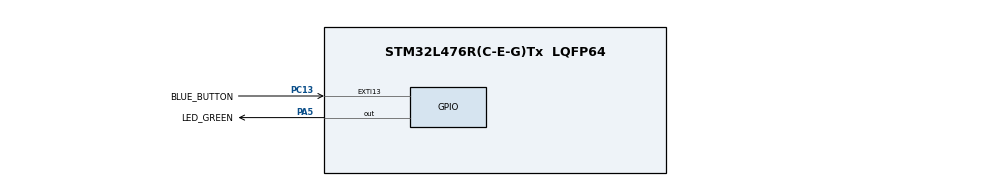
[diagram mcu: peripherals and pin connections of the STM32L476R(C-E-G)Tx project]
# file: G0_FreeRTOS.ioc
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FREERTOS.BinarySemaphores01=Binary_Sem,Dynamic,NULL
FREERTOS.Tasks01=Task1,0,128,Task1_App,Default,NULL,Dynamic,NULL,NULL;Task2,0,128,Task2_App,Default,NULL,Dynamic,NULL,NULL
FREERTOS.configUSE_NEWLIB_REENTRANT=1
Mcu.Family=STM32L4
Mcu.Name=STM32L476R(C-E-G)Tx
Mcu.Package=LQFP64
NVIC.EXTI15_10_IRQn=true\:5\:0\:false\:false\:true\:true\:true\:true\:true
NVIC.PriorityGroup=NVIC_PRIORITYGROUP_4
NVIC.TIM6_DAC_IRQn=true\:15\:0\:false\:false\:true\:false\:false\:true\:true
NVIC.TimeBase=TIM6_DAC_IRQn
NVIC.TimeBaseIP=TIM6
PA13\ (JTMS-SWDIO).Mode=Serial_Wire
PA13\ (JTMS-SWDIO).Signal=SYS_JTMS-SWDIO
PA14\ (JTCK-SWCLK).Mode=Serial_Wire
PA14\ (JTCK-SWCLK).Signal=SYS_JTCK-SWCLK
PA5.GPIO_Label=LED_GREEN
PA5.Signal=GPIO_Output
PC13.GPIO_Label=BLUE_BUTTON
PC13.GPIO_ModeDefaultEXTI=GPIO_MODE_IT_FALLING
PC13.Signal=GPXTI13
ProjectManager.HeapSize=0x200
ProjectManager.StackSize=0x400
ProjectManager.TargetToolchain=STM32CubeIDE
RCC.HSE_VALUE=8000000
RCC.HSI_VALUE=16000000
RCC.LSE_VALUE=32768
RCC.MSI_VALUE=4000000
RCC.VCOOutputFreq_Value=32000000
VP_FREERTOS_VS_CMSIS_V1.Mode=CMSIS_V1
VP_SYS_VS_tim6.Mode=TIM6
board=custom

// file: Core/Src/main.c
/* USER CODE BEGIN Header */
/**
  ******************************************************************************
  * @file           : main.c
  * @brief          : Main program body
  ******************************************************************************
  * @attention
  *
  * Copyright (c) 2023 STMicroelectronics.
  * All rights reserved.
  *
  * This software is licensed under terms that can be found in the LICENSE file
  * in the root directory of this software component.
  * If no LICENSE file comes with this software, it is provided AS-IS.
  *
  ******************************************************************************
  */
/* USER CODE END Header */
#include "main.h"
#include "cmsis_os.h"

osThreadId Task1Handle;
osThreadId Task2Handle;
osSemaphoreId Binary_SemHandle;

void SystemClock_Config(void);
static void MX_GPIO_Init(void);
void Task1_App(void const * argument);
void Task2_App(void const * argument);

int main(void)
{

  /* MCU Configuration--------------------------------------------------------*/

  /* Reset of all peripherals, Initializes the Flash interface and the Systick. */
  HAL_Init();

  /* Configure the system clock */
  SystemClock_Config();

  /* Initialize all configured peripherals */
  MX_GPIO_Init();

  /* Create the semaphores(s) */
  /* definition and creation of Binary_Sem */
  osSemaphoreDef(Binary_Sem);
  Binary_SemHandle = osSemaphoreCreate(osSemaphore(Binary_Sem), 1);

  /* Create the thread(s) */
  /* definition and creation of Task1 */
  osThreadDef(Task1, Task1_App, osPriorityNormal, 0, 128);
  Task1Handle = osThreadCreate(osThread(Task1), NULL);

  /* definition and creation of Task2 */
  osThreadDef(Task2, Task2_App, osPriorityNormal, 0, 128);
  Task2Handle = osThreadCreate(osThread(Task2), NULL);

  /* Start scheduler */
  osKernelStart();

  /* We should never get here as control is now taken by the scheduler */
  /* Infinite loop */
  while (1)
  {

  }
}

void SystemClock_Config(void)
{
  RCC_OscInitTypeDef RCC_OscInitStruct = {0};
  RCC_ClkInitTypeDef RCC_ClkInitStruct = {0};

  /** Configure the main internal regulator output voltage
  */
  if (HAL_PWREx_ControlVoltageScaling(PWR_REGULATOR_VOLTAGE_SCALE1) != HAL_OK)
  {
    Error_Handler();
  }

  /** Initializes the RCC Oscillators according to the specified parameters
  * in the RCC_OscInitTypeDef structure.
  */
  RCC_OscInitStruct.OscillatorType = RCC_OSCILLATORTYPE_MSI;
  RCC_OscInitStruct.MSIState = RCC_MSI_ON;
  RCC_OscInitStruct.MSICalibrationValue = 0;
  RCC_OscInitStruct.MSIClockRange = RCC_MSIRANGE_6;
  RCC_OscInitStruct.PLL.PLLState = RCC_PLL_NONE;
  if (HAL_RCC_OscConfig(&RCC_OscInitStruct) != HAL_OK)
  {
    Error_Handler();
  }

  /** Initializes the CPU, AHB and APB buses clocks
  */
  RCC_ClkInitStruct.ClockType = RCC_CLOCKTYPE_HCLK|RCC_CLOCKTYPE_SYSCLK
                              |RCC_CLOCKTYPE_PCLK1|RCC_CLOCKTYPE_PCLK2;
  RCC_ClkInitStruct.SYSCLKSource = RCC_SYSCLKSOURCE_MSI;
  RCC_ClkInitStruct.AHBCLKDivider = RCC_SYSCLK_DIV1;
  RCC_ClkInitStruct.APB1CLKDivider = RCC_HCLK_DIV1;
  RCC_ClkInitStruct.APB2CLKDivider = RCC_HCLK_DIV1;

  if (HAL_RCC_ClockConfig(&RCC_ClkInitStruct, FLASH_LATENCY_0) != HAL_OK)
  {
    Error_Handler();
  }
}

static void MX_GPIO_Init(void)
{
  GPIO_InitTypeDef GPIO_InitStruct = {0};

  /* GPIO Ports Clock Enable */
  __HAL_RCC_GPIOC_CLK_ENABLE();
  __HAL_RCC_GPIOA_CLK_ENABLE();

  /*Configure GPIO pin Output Level */
  HAL_GPIO_WritePin(LED_GREEN_GPIO_Port, LED_GREEN_Pin, GPIO_PIN_RESET);

  /*Configure GPIO pin : BLUE_BUTTON_Pin */
  GPIO_InitStruct.Pin = BLUE_BUTTON_Pin;
  GPIO_InitStruct.Mode = GPIO_MODE_IT_FALLING;
  GPIO_InitStruct.Pull = GPIO_NOPULL;
  HAL_GPIO_Init(BLUE_BUTTON_GPIO_Port, &GPIO_InitStruct);

  /*Configure GPIO pin : LED_GREEN_Pin */
  GPIO_InitStruct.Pin = LED_GREEN_Pin;
  GPIO_InitStruct.Mode = GPIO_MODE_OUTPUT_PP;
  GPIO_InitStruct.Pull = GPIO_NOPULL;
  GPIO_InitStruct.Speed = GPIO_SPEED_FREQ_LOW;
  HAL_GPIO_Init(LED_GREEN_GPIO_Port, &GPIO_InitStruct);

  /* EXTI interrupt init*/
  HAL_NVIC_SetPriority(EXTI15_10_IRQn, 5, 0);
  HAL_NVIC_EnableIRQ(EXTI15_10_IRQn);

}

/* USER CODE BEGIN 4 */
void HAL_GPIO_EXTI_Callback(uint16_t GPIO_Pin)
{
	if(BLUE_BUTTON_Pin == GPIO_Pin)
	{
		osSemaphoreRelease(Binary_SemHandle);
	}
}

/* USER CODE END 4 */

void Task1_App(void const * argument)
{
  /* USER CODE BEGIN 5 */
  /* Infinite loop */
  for(;;)
  {
	  HAL_GPIO_WritePin(LED_GREEN_GPIO_Port, LED_GREEN_Pin, GPIO_PIN_SET);

	  osSemaphoreWait(Binary_SemHandle, osWaitForever);
	  //osDelay(1000);
  }
  /* USER CODE END 5 */
}

void Task2_App(void const * argument)
{
  /* USER CODE BEGIN Task2_App */
  /* Infinite loop */
  for(;;)
  {
	  HAL_GPIO_WritePin(LED_GREEN_GPIO_Port, LED_GREEN_Pin, GPIO_PIN_RESET);
	  osDelay(1300);
  }
  /* USER CODE END Task2_App */
}

void HAL_TIM_PeriodElapsedCallback(TIM_HandleTypeDef *htim)
{
  if (htim->Instance == TIM6) {
    HAL_IncTick();
  }
}

void Error_Handler(void)
{
  __disable_irq();
  while (1)
  {
  }
}
